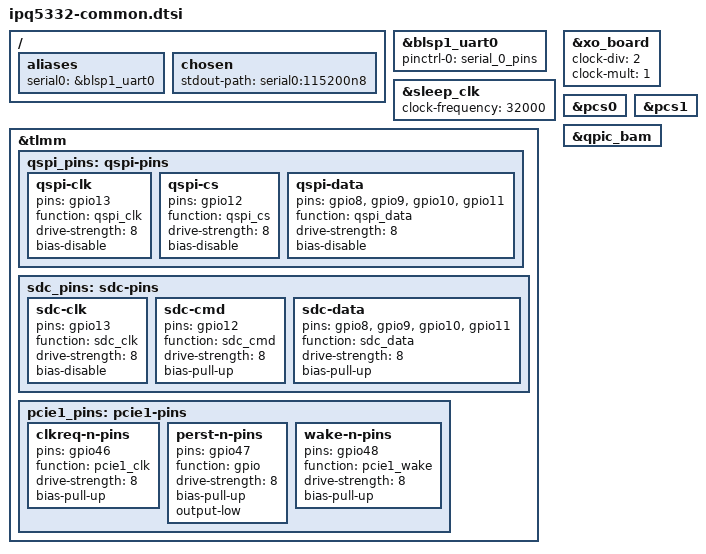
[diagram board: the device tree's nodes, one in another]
// SPDX-License-Identifier: (GPL-2.0+ OR BSD-3-Clause)

#include "ipq5332.dtsi"

#include <dt-bindings/gpio/gpio.h>
#include <dt-bindings/input/input.h>
#include <dt-bindings/leds/common.h>

/ {
	aliases {
		serial0 = &blsp1_uart0;
	};

	chosen {
		stdout-path = "serial0:115200n8";
	};
};

&blsp1_uart0 {
	status = "okay";

	pinctrl-0 = <&serial_0_pins>;
	pinctrl-names = "default";
};

&sleep_clk {
	clock-frequency = <32000>;
};

&xo_board {
	clock-div = <2>;
	clock-mult = <1>;
};

&tlmm {
	qspi_pins: qspi-pins {
		qspi-clk {
			pins = "gpio13";
			function = "qspi_clk";
			drive-strength = <8>;
			bias-disable;
		};

		qspi-cs {
			pins = "gpio12";
			function = "qspi_cs";
			drive-strength = <8>;
			bias-disable;
		};

		qspi-data {
			pins = "gpio8", "gpio9", "gpio10", "gpio11";
			function = "qspi_data";
			drive-strength = <8>;
			bias-disable;
		};
	};

	sdc_pins: sdc-pins {
		sdc-clk {
			pins = "gpio13";
			function = "sdc_clk";
			drive-strength = <8>;
			bias-disable;
		};

		sdc-cmd {
			pins = "gpio12";
			function = "sdc_cmd";
			drive-strength = <8>;
			bias-pull-up;
		};

		sdc-data {
			pins = "gpio8", "gpio9", "gpio10", "gpio11";
			function = "sdc_data";
			drive-strength = <8>;
			bias-pull-up;
		};
	};

	pcie1_pins: pcie1-pins {
		clkreq-n-pins {
			pins = "gpio46";
			function = "pcie1_clk";
			drive-strength = <8>;
			bias-pull-up;
		};

		perst-n-pins {
			pins = "gpio47";
			function = "gpio";
			drive-strength = <8>;
			bias-pull-up;
			output-low;
		};

		wake-n-pins {
			pins = "gpio48";
			function = "pcie1_wake";
			drive-strength = <8>;
			bias-pull-up;
		};
	};
};

&pcs0 {
	status = "okay";
};

&pcs1 {
	status = "okay";
};

&qpic_bam {
	status = "okay";
};
